# LAN9255ZMX020 device description
Architecture: CORTEX-M4; Family: LAN9255; Series: LAN9255ZMX
Registers are 32-bit, read-write, reset 0x0 unless marked. A register's access mark holds for its fields unless they carry their own. Offsets are from the block's base; [hi:lo] are bit positions; {n}, {i} and the like mark numbered series; 'fields as' and 'values as' point back to an identical list.

## CMCC — Cortex M Cache Controller
Instances: CMCC 0x41006000
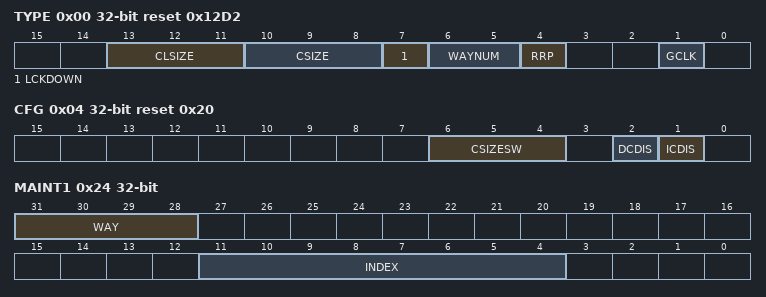
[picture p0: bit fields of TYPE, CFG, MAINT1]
0x00 TYPE ro reset 0x12D2 — Cache Type Register
  [13:11] CLSIZE — Cache Line Size
    0=CLSIZE_4B (Cache Line Size is 4 bytes); 1=CLSIZE_8B (Cache Line Size is 8 bytes); 2=CLSIZE_16B (Cache Line Size is 16 bytes); 3=CLSIZE_32B (Cache Line Size is 32 bytes); 4=CLSIZE_64B (Cache Line Size is 64 bytes); 5=CLSIZE_128B (Cache Line Size is 128 bytes)
  [10:8] CSIZE — Cache Size
    0=CSIZE_1KB (Cache Size is 1 KB); 1=CSIZE_2KB (Cache Size is 2 KB); 2=CSIZE_4KB (Cache Size is 4 KB); 3=CSIZE_8KB (Cache Size is 8 KB); 4=CSIZE_16KB (Cache Size is 16 KB); 5=CSIZE_32KB (Cache Size is 32 KB); 6=CSIZE_64KB (Cache Size is 64 KB)
  [7] LCKDOWN — Lock Down supported
  [6:5] WAYNUM — Number of Way
    0=DMAPPED (Direct Mapped Cache); 1=ARCH2WAY (2-WAY set associative); 2=ARCH4WAY (4-WAY set associative)
  [4] RRP — Round Robin Policy supported
  [1] GCLK — dynamic Clock Gating supported
0x04 CFG reset 0x20 — Cache Configuration Register
  [6:4] CSIZESW — Cache size configured by software
    0=CONF_CSIZE_1KB (The Cache Size is configured to 1KB); 1=CONF_CSIZE_2KB (The Cache Size is configured to 2KB); 2=CONF_CSIZE_4KB (The Cache Size is configured to 4KB); 3=CONF_CSIZE_8KB (The Cache Size is configured to 8KB); 4=CONF_CSIZE_16KB (The Cache Size is configured to 16KB); 5=CONF_CSIZE_32KB (The Cache Size is configured to 32KB); 6=CONF_CSIZE_64KB (The Cache Size is configured to 64KB)
  [2] DCDIS — Data Cache Disable
  [1] ICDIS — Instruction Cache Disable
0x08 CTRL wo — Cache Control Register
  [0] CEN — Cache Controller Enable
0x0C SR ro — Cache Status Register
  [0] CSTS — Cache Controller Status
0x10 LCKWAY — Cache Lock per Way Register
  [3:0] LCKWAY — Lockdown way Register
0x20 MAINT0 wo — Cache Maintenance Register 0
  [0] INVALL — Cache Controller invalidate All
0x24 MAINT1 wo — Cache Maintenance Register 1
  [31:28] WAY — Invalidate Way
    {v}=Way {v} is selection for index invalidation (v=0..3)
  [11:4] INDEX — Invalidate Index
0x28 MCFG — Cache Monitor Configuration Register
  [1:0] MODE — Cache Controller Monitor Counter Mode
    0=CYCLE_COUNT (Cycle counter); 1=IHIT_COUNT (Instruction hit counter); 2=DHIT_COUNT (Data hit counter)
0x2C MEN — Cache Monitor Enable Register
  [0] MENABLE — Cache Controller Monitor Enable
0x30 MCTRL wo — Cache Monitor Control Register
  [0] SWRST — Cache Controller Software Reset
0x34 MSR ro — Cache Monitor Status Register
  [31:0] EVENT_CNT — Monitor Event Counter

## DAC — Digital-to-Analog Converter
Instances: DAC 0x43002400
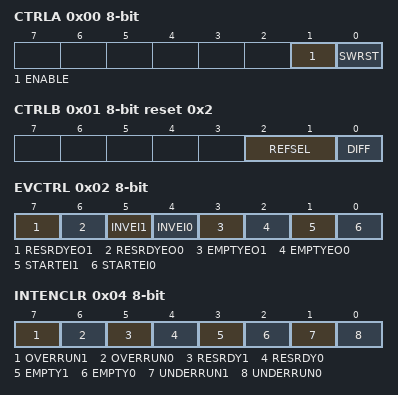
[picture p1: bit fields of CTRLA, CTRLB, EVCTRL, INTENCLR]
0x00 CTRLA 8-bit (WSYNC) — Control A
  [1] ENABLE — Enable DAC Controller
  [0] SWRST — Software Reset
0x01 CTRLB 8-bit reset 0x2 — Control B
  [2:1] REFSEL — Reference Selection for DAC0/1
    0=VREFPU (External reference unbuffered); 1=VDDANA (Analog supply); 2=VREFPB (External reference buffered); 3=INTREF (Internal bandgap reference)
  [0] DIFF — Differential mode enable
0x02 EVCTRL 8-bit — Event Control
  [7] RESRDYEO1 — Result Ready Event Output 1
  [6] RESRDYEO0 — Result Ready Event Output 0
  [5] INVEI1 — Enable Invertion of DAC 1 input event
  [4] INVEI0 — Enable Invertion of DAC 0 input event
  [3] EMPTYEO1 — Data Buffer Empty Event Output DAC 1
  [2] EMPTYEO0 — Data Buffer Empty Event Output DAC 0
  [1] STARTEI1 — Start Conversion Event Input DAC 1
  [0] STARTEI0 — Start Conversion Event Input DAC 0
0x04 INTENCLR 8-bit (atomic clear) — Interrupt Enable Clear
  [7] OVERRUN1 — Overrun 1 Interrupt Enable
  [6] OVERRUN0 — Overrun 0 Interrupt Enable
  [5] RESRDY1 — Result 1 Ready Interrupt Enable
  [4] RESRDY0 — Result 0 Ready Interrupt Enable
  [3] EMPTY1 — Data Buffer 1 Empty Interrupt Enable
  [2] EMPTY0 — Data Buffer 0 Empty Interrupt Enable
  [1] UNDERRUN1 — Underrun 1 Interrupt Enable
  [0] UNDERRUN0 — Underrun 0 Interrupt Enable
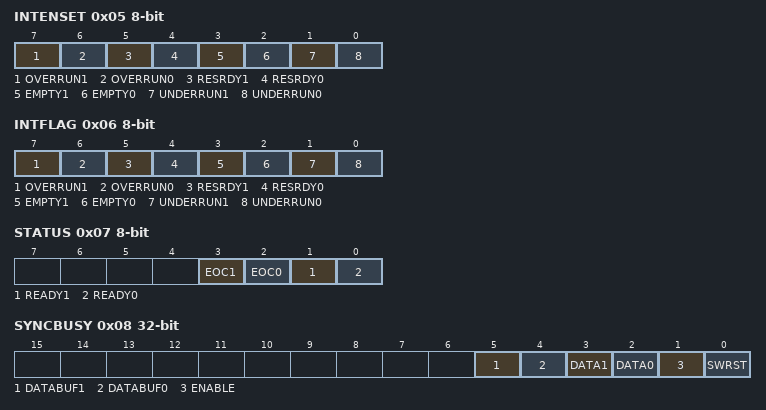
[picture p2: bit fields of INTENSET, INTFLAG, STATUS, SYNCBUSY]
0x05 INTENSET 8-bit (atomic set) — Interrupt Enable Set
  fields as INTENCLR
0x06 INTFLAG 8-bit (atomic clear) — Interrupt Flag Status and Clear
  [7] OVERRUN1 — Result 1 Overrun
  [6] OVERRUN0 — Result 0 Overrun
  [5] RESRDY1 — Result 1 Ready
  [4] RESRDY0 — Result 0 Ready
  [3] EMPTY1 — Data Buffer 1 Empty
  [2] EMPTY0 — Data Buffer 0 Empty
  [1] UNDERRUN1 — Result 1 Underrun
  [0] UNDERRUN0 — Result 0 Underrun
0x07 STATUS 8-bit ro
  [3] EOC1 — DAC 1 End of Conversion
  [2] EOC0 — DAC 0 End of Conversion
  [1] READY1 — DAC 1 Startup Ready
  [0] READY0 — DAC 0 Startup Ready
0x08 SYNCBUSY ro — Synchronization Busy
  [5] DATABUF1 — Data Buffer DAC 1
  [4] DATABUF0 — Data Buffer DAC 0
  [3] DATA1 — Data DAC 1
  [2] DATA0 — Data DAC 0
  [1] ENABLE — DAC Enable Status
  [0] SWRST — Software Reset
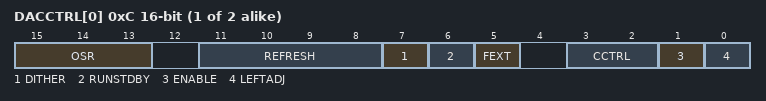
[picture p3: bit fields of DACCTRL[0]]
{0xC+2i} DACCTRL[{i}] (i=0..1) 16-bit — DAC n Control
  [15:13] OSR — Sampling Rate
    0=No Over Sampling; 1=2x Over Sampling Ratio; 2=4x Over Sampling Ratio; 3=8x Over Sampling Ratio; 4=16x Over Sampling Ratio; 5=32x Over Sampling Ratio
  [11:8] REFRESH — Refresh period
    0=Do not Refresh; 1=Refresh every 30 us; 2=Refresh every 60 us; 3=Refresh every 90 us; 4=Refresh every 120 us; 5=Refresh every 150 us; 6=Refresh every 180 us; 7=Refresh every 210 us; 8=Refresh every 240 us; 9=Refresh every 270 us; 10=Refresh every 300 us; 11=Refresh every 330 us; 12=Refresh every 360 us; 13=Refresh every 390 us; 14=Refresh every 420 us; 15=Refresh every 450 us
  [7] DITHER — Dithering Mode
  [6] RUNSTDBY — Run in Standby
  [5] FEXT — Standalone Filter
  [3:2] CCTRL — Current Control
    0=CC100K (100kSPS); 1=CC1M (500kSPS); 2=CC12M (1MSPS)
  [1] ENABLE — Enable DAC0
  [0] LEFTADJ — Left Adjusted Data
{0x10+2i} DATA[{i}] (i=0..1) 16-bit wo (WSYNC) — DAC n Data
  [15:0] DATA — DAC0 Data
{0x14+2i} DATABUF[{i}] (i=0..1) 16-bit wo (WSYNC) — DAC n Data Buffer
  [15:0] DATABUF — DAC0 Data Buffer
0x18 DBGCTRL 8-bit — Debug Control
  [0] DBGRUN — Debug Run
{0x1C+2i} RESULT[{i}] (i=0..1) 16-bit ro — Filter Result

## Notices in the file
Copyright (c) 2018 Microchip Technology Inc.
SPDX-License-Identifier: Apache-2.0
Licensed under the Apache License, Version 2.0 (the "License");
you may not use this file except in compliance with the License.
You may obtain a copy of the License at
http://www.apache.org/licenses/LICENSE-2.0
Unless required by applicable law or agreed to in writing, software
distributed under the License is distributed on an "AS IS" BASIS,
WITHOUT WARRANTIES OR CONDITIONS OF ANY KIND, either express or implied.
See the License for the specific language governing permissions and
limitations under the License.
